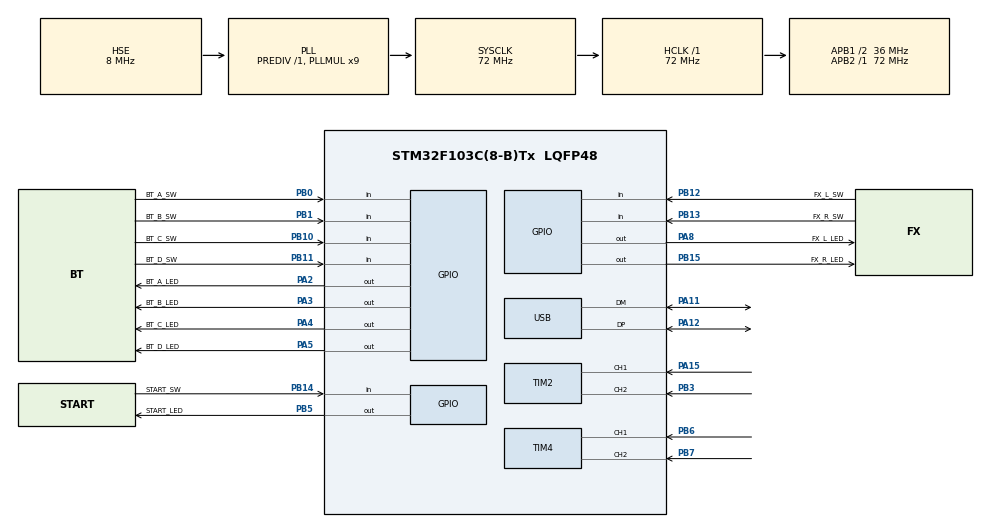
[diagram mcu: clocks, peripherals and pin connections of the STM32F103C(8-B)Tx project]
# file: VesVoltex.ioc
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Mcu.Family=STM32F1
Mcu.Name=STM32F103C(8-B)Tx
Mcu.Package=LQFP48
NVIC.PriorityGroup=NVIC_PRIORITYGROUP_4
NVIC.USB_LP_CAN1_RX0_IRQn=true\:0\:0\:false\:false\:true\:false\:true\:true
PA11.Mode=Device
PA11.Signal=USB_DM
PA12.Mode=Device
PA12.Signal=USB_DP
PA13.Mode=Serial_Wire
PA13.Signal=SYS_JTMS-SWDIO
PA14.Mode=Serial_Wire
PA14.Signal=SYS_JTCK-SWCLK
PA15.Signal=S_TIM2_CH1_ETR
PA2.GPIO_Label=BT_A_LED
PA2.GPIO_ModeDefaultOutputPP=GPIO_MODE_OUTPUT_PP
PA2.GPIO_PuPd=GPIO_NOPULL
PA2.GPIO_Speed=GPIO_SPEED_FREQ_LOW
PA2.PinState=GPIO_PIN_RESET
PA2.Signal=GPIO_Output
PA3.GPIO_Label=BT_B_LED
PA3.GPIO_ModeDefaultOutputPP=GPIO_MODE_OUTPUT_PP
PA3.GPIO_PuPd=GPIO_NOPULL
PA3.GPIO_Speed=GPIO_SPEED_FREQ_LOW
PA3.PinState=GPIO_PIN_RESET
PA3.Signal=GPIO_Output
PA4.GPIO_Label=BT_C_LED
PA4.GPIO_ModeDefaultOutputPP=GPIO_MODE_OUTPUT_PP
PA4.GPIO_PuPd=GPIO_NOPULL
PA4.GPIO_Speed=GPIO_SPEED_FREQ_LOW
PA4.PinState=GPIO_PIN_RESET
PA4.Signal=GPIO_Output
PA5.GPIO_Label=BT_D_LED
PA5.GPIO_ModeDefaultOutputPP=GPIO_MODE_OUTPUT_PP
PA5.GPIO_PuPd=GPIO_NOPULL
PA5.GPIO_Speed=GPIO_SPEED_FREQ_LOW
PA5.PinState=GPIO_PIN_RESET
PA5.Signal=GPIO_Output
PA8.GPIO_Label=FX_L_LED
PA8.GPIO_ModeDefaultOutputPP=GPIO_MODE_OUTPUT_PP
PA8.GPIO_PuPd=GPIO_NOPULL
PA8.GPIO_Speed=GPIO_SPEED_FREQ_LOW
PA8.PinState=GPIO_PIN_RESET
PA8.Signal=GPIO_Output
PB0.GPIO_Label=BT_A_SW
PB0.GPIO_PuPd=GPIO_PULLUP
PB0.Signal=GPIO_Input
PB1.GPIO_Label=BT_B_SW
PB1.GPIO_PuPd=GPIO_PULLUP
PB1.Signal=GPIO_Input
PB10.GPIO_Label=BT_C_SW
PB10.GPIO_PuPd=GPIO_PULLUP
PB10.Signal=GPIO_Input
PB11.GPIO_Label=BT_D_SW
PB11.GPIO_PuPd=GPIO_PULLUP
PB11.Signal=GPIO_Input
PB12.GPIO_Label=FX_L_SW
PB12.GPIO_PuPd=GPIO_PULLUP
PB12.Signal=GPIO_Input
PB13.GPIO_Label=FX_R_SW
PB13.GPIO_PuPd=GPIO_PULLUP
PB13.Signal=GPIO_Input
PB14.GPIO_Label=START_SW
PB14.GPIO_PuPd=GPIO_PULLUP
PB14.Signal=GPIO_Input
PB15.GPIO_Label=FX_R_LED
PB15.GPIO_ModeDefaultOutputPP=GPIO_MODE_OUTPUT_PP
PB15.GPIO_PuPd=GPIO_NOPULL
PB15.GPIO_Speed=GPIO_SPEED_FREQ_LOW
PB15.PinState=GPIO_PIN_RESET
PB15.Signal=GPIO_Output
PB3.Signal=S_TIM2_CH2
PB5.GPIO_Label=START_LED
PB5.GPIO_ModeDefaultOutputPP=GPIO_MODE_OUTPUT_PP
PB5.GPIO_PuPd=GPIO_NOPULL
PB5.GPIO_Speed=GPIO_SPEED_FREQ_LOW
PB5.PinState=GPIO_PIN_RESET
PB5.Signal=GPIO_Output
PB6.Signal=S_TIM4_CH1
PB7.Signal=S_TIM4_CH2
PD0-OSC_IN.Mode=HSE-External-Oscillator
PD0-OSC_IN.Signal=RCC_OSC_IN
PD1-OSC_OUT.Mode=HSE-External-Oscillator
PD1-OSC_OUT.Signal=RCC_OSC_OUT
ProjectManager.HeapSize=0x200
ProjectManager.StackSize=0x800
ProjectManager.TargetToolchain=CMake
RCC.AHBFreq_Value=72000000
RCC.APB1CLKDivider=RCC_HCLK_DIV2
RCC.APB1Freq_Value=36000000
RCC.APB1TimFreq_Value=72000000
RCC.APB2Freq_Value=72000000
RCC.APB2TimFreq_Value=72000000
RCC.HCLKFreq_Value=72000000
RCC.PLLMUL=RCC_PLL_MUL9
RCC.PLLSourceVirtual=RCC_PLLSOURCE_HSE
RCC.SYSCLKFreq_VALUE=72000000
RCC.SYSCLKSource=RCC_SYSCLKSOURCE_PLLCLK
RCC.USBFreq_Value=48000000
RCC.USBPrescaler=RCC_USBCLKSOURCE_PLL_DIV1_5
SH.S_TIM2_CH1_ETR.0=TIM2_CH1,Encoder_Interface
SH.S_TIM2_CH2.0=TIM2_CH2,Encoder_Interface
SH.S_TIM4_CH1.0=TIM4_CH1,Encoder_Interface
SH.S_TIM4_CH2.0=TIM4_CH2,Encoder_Interface
TIM2.EncoderMode=TIM_ENCODERMODE_TI12
TIM2.IC1Filter=4
TIM2.IC2Filter=4
TIM4.EncoderMode=TIM_ENCODERMODE_TI12
TIM4.IC1Filter=4
TIM4.IC2Filter=4
USB_DEVICE.CLASS_NAME_FS=CUSTOM_HID
USB_DEVICE.CONFIGURATION_STRING_CUSTOMHID_FS=VesVoltex HID Config
USB_DEVICE.CUSTOM_HID_FS_BINTERVAL=0x1
USB_DEVICE.INTERFACE_STRING_CUSTOMHID_FS=VesVoltex HID Interface
USB_DEVICE.MANUFACTURER_STRING=MoeClub Ltd
USB_DEVICE.PRODUCT_STRING_CUSTOMHID_FS=VesVoltex Game Controller
USB_DEVICE.USBD_CUSTOMHID_OUTREPORT_BUF_SIZE=8
USB_DEVICE.USBD_CUSTOM_HID_REPORT_DESC_SIZE=64
USB_DEVICE.USBD_SELF_POWERED=0
USB_DEVICE.VirtualMode=CustomHid
USB_DEVICE.VirtualModeFS=Custom_Hid_FS
VP_USB_DEVICE_VS_USB_DEVICE_CUSTOM_HID_FS.Mode=CUSTOM_HID_FS
board=custom

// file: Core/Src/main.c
/* USER CODE BEGIN Header */
/**
  ******************************************************************************
  * @file           : main.c
  * @brief          : Main program body
  ******************************************************************************
  * @attention
  *
  * Copyright (c) 2026 STMicroelectronics.
  * All rights reserved.
  *
  * This software is licensed under terms that can be found in the LICENSE file
  * in the root directory of this software component.
  * If no LICENSE file comes with this software, it is provided AS-IS.
  *
  ******************************************************************************
  */
/* USER CODE END Header */
#include "main.h"
#include "tim.h"
#include "usb_device.h"
#include "gpio.h"

/* USER CODE BEGIN Includes */
#include "controller.h"
/* USER CODE END Includes */

void SystemClock_Config(void);

int main(void)
{

  /* MCU Configuration--------------------------------------------------------*/

  /* Reset of all peripherals, Initializes the Flash interface and the Systick. */
  HAL_Init();

  /* Configure the system clock */
  SystemClock_Config();

  /* USER CODE BEGIN SysInit */
  GPIO_InitTypeDef GPIO_InitStruct = {0};

  __HAL_RCC_GPIOA_CLK_ENABLE();
  HAL_GPIO_WritePin(GPIOA, GPIO_PIN_12, GPIO_PIN_RESET);
  GPIO_InitStruct.Pin = GPIO_PIN_12;
  GPIO_InitStruct.Mode = GPIO_MODE_OUTPUT_PP;
  GPIO_InitStruct.Speed = GPIO_SPEED_FREQ_LOW;
  HAL_GPIO_Init(GPIOA, &GPIO_InitStruct);
  HAL_Delay(100);
  HAL_GPIO_DeInit(GPIOA, GPIO_PIN_12);
  /* USER CODE END SysInit */

  /* Initialize all configured peripherals */
  MX_GPIO_Init();
  MX_TIM2_Init();
  MX_TIM4_Init();
  MX_USB_DEVICE_Init();
  /* USER CODE BEGIN 2 */
  Controller_Init();
  /* USER CODE END 2 */

  /* Infinite loop */
  while (1)
  {

    /* USER CODE BEGIN 3 */
    Controller_Task();
  }
  /* USER CODE END 3 */
}

void SystemClock_Config(void)
{
  RCC_OscInitTypeDef RCC_OscInitStruct = {0};
  RCC_ClkInitTypeDef RCC_ClkInitStruct = {0};
  RCC_PeriphCLKInitTypeDef PeriphClkInit = {0};

  /** Initializes the RCC Oscillators according to the specified parameters
  * in the RCC_OscInitTypeDef structure.
  */
  RCC_OscInitStruct.OscillatorType = RCC_OSCILLATORTYPE_HSE;
  RCC_OscInitStruct.HSEState = RCC_HSE_ON;
  RCC_OscInitStruct.HSEPredivValue = RCC_HSE_PREDIV_DIV1;
  RCC_OscInitStruct.HSIState = RCC_HSI_ON;
  RCC_OscInitStruct.PLL.PLLState = RCC_PLL_ON;
  RCC_OscInitStruct.PLL.PLLSource = RCC_PLLSOURCE_HSE;
  RCC_OscInitStruct.PLL.PLLMUL = RCC_PLL_MUL9;
  if (HAL_RCC_OscConfig(&RCC_OscInitStruct) != HAL_OK)
  {
    Error_Handler();
  }

  /** Initializes the CPU, AHB and APB buses clocks
  */
  RCC_ClkInitStruct.ClockType = RCC_CLOCKTYPE_HCLK|RCC_CLOCKTYPE_SYSCLK
                              |RCC_CLOCKTYPE_PCLK1|RCC_CLOCKTYPE_PCLK2;
  RCC_ClkInitStruct.SYSCLKSource = RCC_SYSCLKSOURCE_PLLCLK;
  RCC_ClkInitStruct.AHBCLKDivider = RCC_SYSCLK_DIV1;
  RCC_ClkInitStruct.APB1CLKDivider = RCC_HCLK_DIV2;
  RCC_ClkInitStruct.APB2CLKDivider = RCC_HCLK_DIV1;

  if (HAL_RCC_ClockConfig(&RCC_ClkInitStruct, FLASH_LATENCY_2) != HAL_OK)
  {
    Error_Handler();
  }
  PeriphClkInit.PeriphClockSelection = RCC_PERIPHCLK_USB;
  PeriphClkInit.UsbClockSelection = RCC_USBCLKSOURCE_PLL_DIV1_5;
  if (HAL_RCCEx_PeriphCLKConfig(&PeriphClkInit) != HAL_OK)
  {
    Error_Handler();
  }
}

void Error_Handler(void)
{
  __disable_irq();
  while (1)
  {
  }
}
